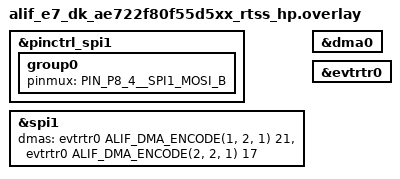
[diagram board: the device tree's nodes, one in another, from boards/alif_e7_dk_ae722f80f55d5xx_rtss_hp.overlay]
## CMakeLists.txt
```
cmake_minimum_required(VERSION 3.13.1)

set(EXTRA_CONF_FILE ../../base.conf)

# adds out-of-tree custom drivers as a Zephyr extra module (this line should be above the find_package line)
set(PROJECT_DIR ${CMAKE_CURRENT_SOURCE_DIR}/../..)
list(APPEND ZEPHYR_EXTRA_MODULES ${PROJECT_DIR}/drivers)

# Ethernet + zperf benchmark. The MAC is a single shared peripheral, so only one
# core may own it at a time (see project/apps/common/eth.overlay). HP defaults
# OFF (HE owns Ethernet by default); benchmark HP with -DAPP_ETHERNET=ON AND
# flash HP only, so the two cores never drive the MAC simultaneously.
option(APP_ETHERNET "Build with the Alif Ethernet + zperf benchmark" OFF)
if(APP_ETHERNET)
  list(APPEND EXTRA_CONF_FILE ${PROJECT_DIR}/apps/common/eth_zperf.conf)
  list(APPEND EXTRA_DTC_OVERLAY_FILE ${PROJECT_DIR}/apps/common/eth.overlay)
endif()

find_package(Zephyr REQUIRED HINTS $ENV{ZEPHYR_BASE})

# Warnings as errors for C++ (C/ASM already handled by CONFIG_COMPILER_WARNINGS_AS_ERRORS)
zephyr_compile_options($<$<COMPILE_LANGUAGE:CXX>:$<TARGET_PROPERTY:compiler,warnings_as_errors>>)

project(hp_app)

zephyr_include_directories(${CMAKE_CURRENT_SOURCE_DIR})

target_sources(app PRIVATE main.cpp )
```

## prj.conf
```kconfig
#### Serial config ####
CONFIG_SERIAL=y
CONFIG_GPIO=y
CONFIG_UART_CONSOLE=y
CONFIG_UART_INTERRUPT_DRIVEN=y

#### SPI through DMA ####
CONFIG_SPI=y
CONFIG_SPI_DW_USE_DMA=y
CONFIG_DMA=y
# The DMA event router logs every channel configuration at INFO level, which drops the test results.
CONFIG_DMA_ALIF_EVENT_ROUTER_LOG_LEVEL_WRN=y
```

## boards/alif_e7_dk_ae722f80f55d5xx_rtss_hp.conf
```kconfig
#CONFIG_ARM_ETHOS_U55=y
#CONFIG_ETHOS_U=y

#CONFIG_ETHOS_U_LOGGING=y
#CONFIG_LOG_DEFAULT_LEVEL=4
```

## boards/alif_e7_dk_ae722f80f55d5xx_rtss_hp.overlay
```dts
#include <zephyr/dt-bindings/dma/alif_dma_event_router.h>

/* SPI1 in internal loopback (SPI_MODE_LOOP) through DMA: nothing to wire. Only MOSI is muxed. */
&pinctrl_spi1 {
	group0 {
		pinmux = <PIN_P8_4__SPI1_MOSI_B>;
	};
};

&spi1 {
	status = "okay";
	/* DMA0 group 2: SPI1 TX is peripheral request 21, SPI1 RX request 17 (E7 HWRM, DMA0 requests mapping) */
	dmas = <&evtrtr0 ALIF_DMA_ENCODE(1, 2, 1) 21>, <&evtrtr0 ALIF_DMA_ENCODE(2, 2, 1) 17>;
	dma-names = "txdma", "rxdma";
};

&dma0 {
	status = "okay";
};

&evtrtr0 {
	status = "okay";
};
```

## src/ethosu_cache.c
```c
/* Override cache maintenance functions used by ethosu driver
 * This file provides concrete implementations of the weak
 * functions `ethosu_flush_dcache` and `ethosu_invalidate_dcache`
 * so the HAL driver will perform correct cache maintenance on Zephyr.
 */

#include <zephyr/cache.h>
#include <stdint.h>
#include <stddef.h>

void ethosu_flush_dcache(uint32_t *p, size_t bytes)
{
    if (p == NULL) {
        sys_cache_data_flush_all();
    } else {
        sys_cache_data_flush_range((void *)p, bytes);
    }
}

void ethosu_invalidate_dcache(uint32_t *p, size_t bytes)
{
    if (p == NULL) {
        sys_cache_data_invd_all();
    } else {
        sys_cache_data_invd_range((void *)p, bytes);
    }
}
```

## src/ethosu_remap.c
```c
/* Override ethosu_address_remap to map local CPU addresses (ITCM/DTCM)
 * to the physical/global addresses exposed on the AXI bus for the NPU.
 *
 * The values below are taken from the generated devicetree in the build
 * and correspond to the `zephyr,memory-region` global_base shown in
 * `build/hp/zephyr/dts.cmake` / `zephyr.dts.pre`.
 */

#include <stdint.h>

uint64_t __attribute__((weak)) ethosu_address_remap(uint64_t address, int index)
{
    (void)index;

    /* ITCM on this platform: CPU addr 0x00000000 -> NPU visible 0x50000000 */
    const uint64_t ITCM_CPU_BASE = 0x00000000ull;
    const uint64_t ITCM_SIZE = 0x40000ull; /* 256 KiB */
    const uint64_t ITCM_GLOBAL = 0x50000000ull;

    /* DTCM on this platform: CPU addr 0x20000000 -> NPU visible 0x50800000 */
    const uint64_t DTCM_CPU_BASE = 0x20000000ull;
    const uint64_t DTCM_SIZE = 0x100000ull; /* 1 MiB */
    const uint64_t DTCM_GLOBAL = 0x50800000ull;

    if (address >= ITCM_CPU_BASE && address < (ITCM_CPU_BASE + ITCM_SIZE))
    {
        return (address - ITCM_CPU_BASE) + ITCM_GLOBAL;
    }

    if (address >= DTCM_CPU_BASE && address < (DTCM_CPU_BASE + DTCM_SIZE))
    {
        return (address - DTCM_CPU_BASE) + DTCM_GLOBAL;
    }

    /* Default: no remap */
    return address;
}
```
